VERSION ""

NS_ :

BS_:

BU_: ECU Tester

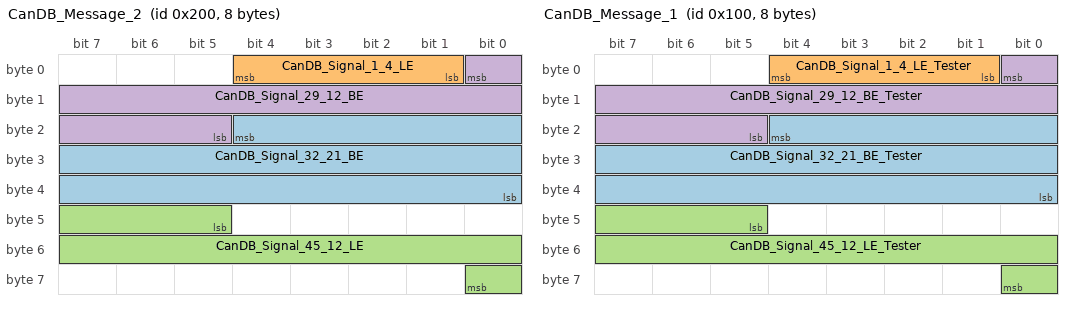
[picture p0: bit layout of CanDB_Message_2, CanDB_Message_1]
BO_ 512 CanDB_Message_2: 8 ECU
 SG_ CanDB_Signal_32_21_BE : 20|21@0+ (1,0) [0|0] "" Vector__XXX
 SG_ CanDB_Signal_1_4_LE : 1|4@1+ (1,0) [0|0] "" Vector__XXX
 SG_ CanDB_Signal_45_12_LE : 45|12@1- (1,0) [0|0] "" Vector__XXX
 SG_ CanDB_Signal_29_12_BE : 0|12@0- (1,0) [0|0] "" Vector__XXX

BO_ 256 CanDB_Message_1: 8 Tester
 SG_ CanDB_Signal_32_21_BE_Tester : 20|21@0+ (1,0) [0|0] "" Vector__XXX
 SG_ CanDB_Signal_1_4_LE_Tester : 1|4@1+ (1,0) [0|0] "" Vector__XXX
 SG_ CanDB_Signal_45_12_LE_Tester : 45|12@1- (1,0) [0|0] "" Vector__XXX
 SG_ CanDB_Signal_29_12_BE_Tester : 0|12@0- (1,0) [0|0] "" Vector__XXX
